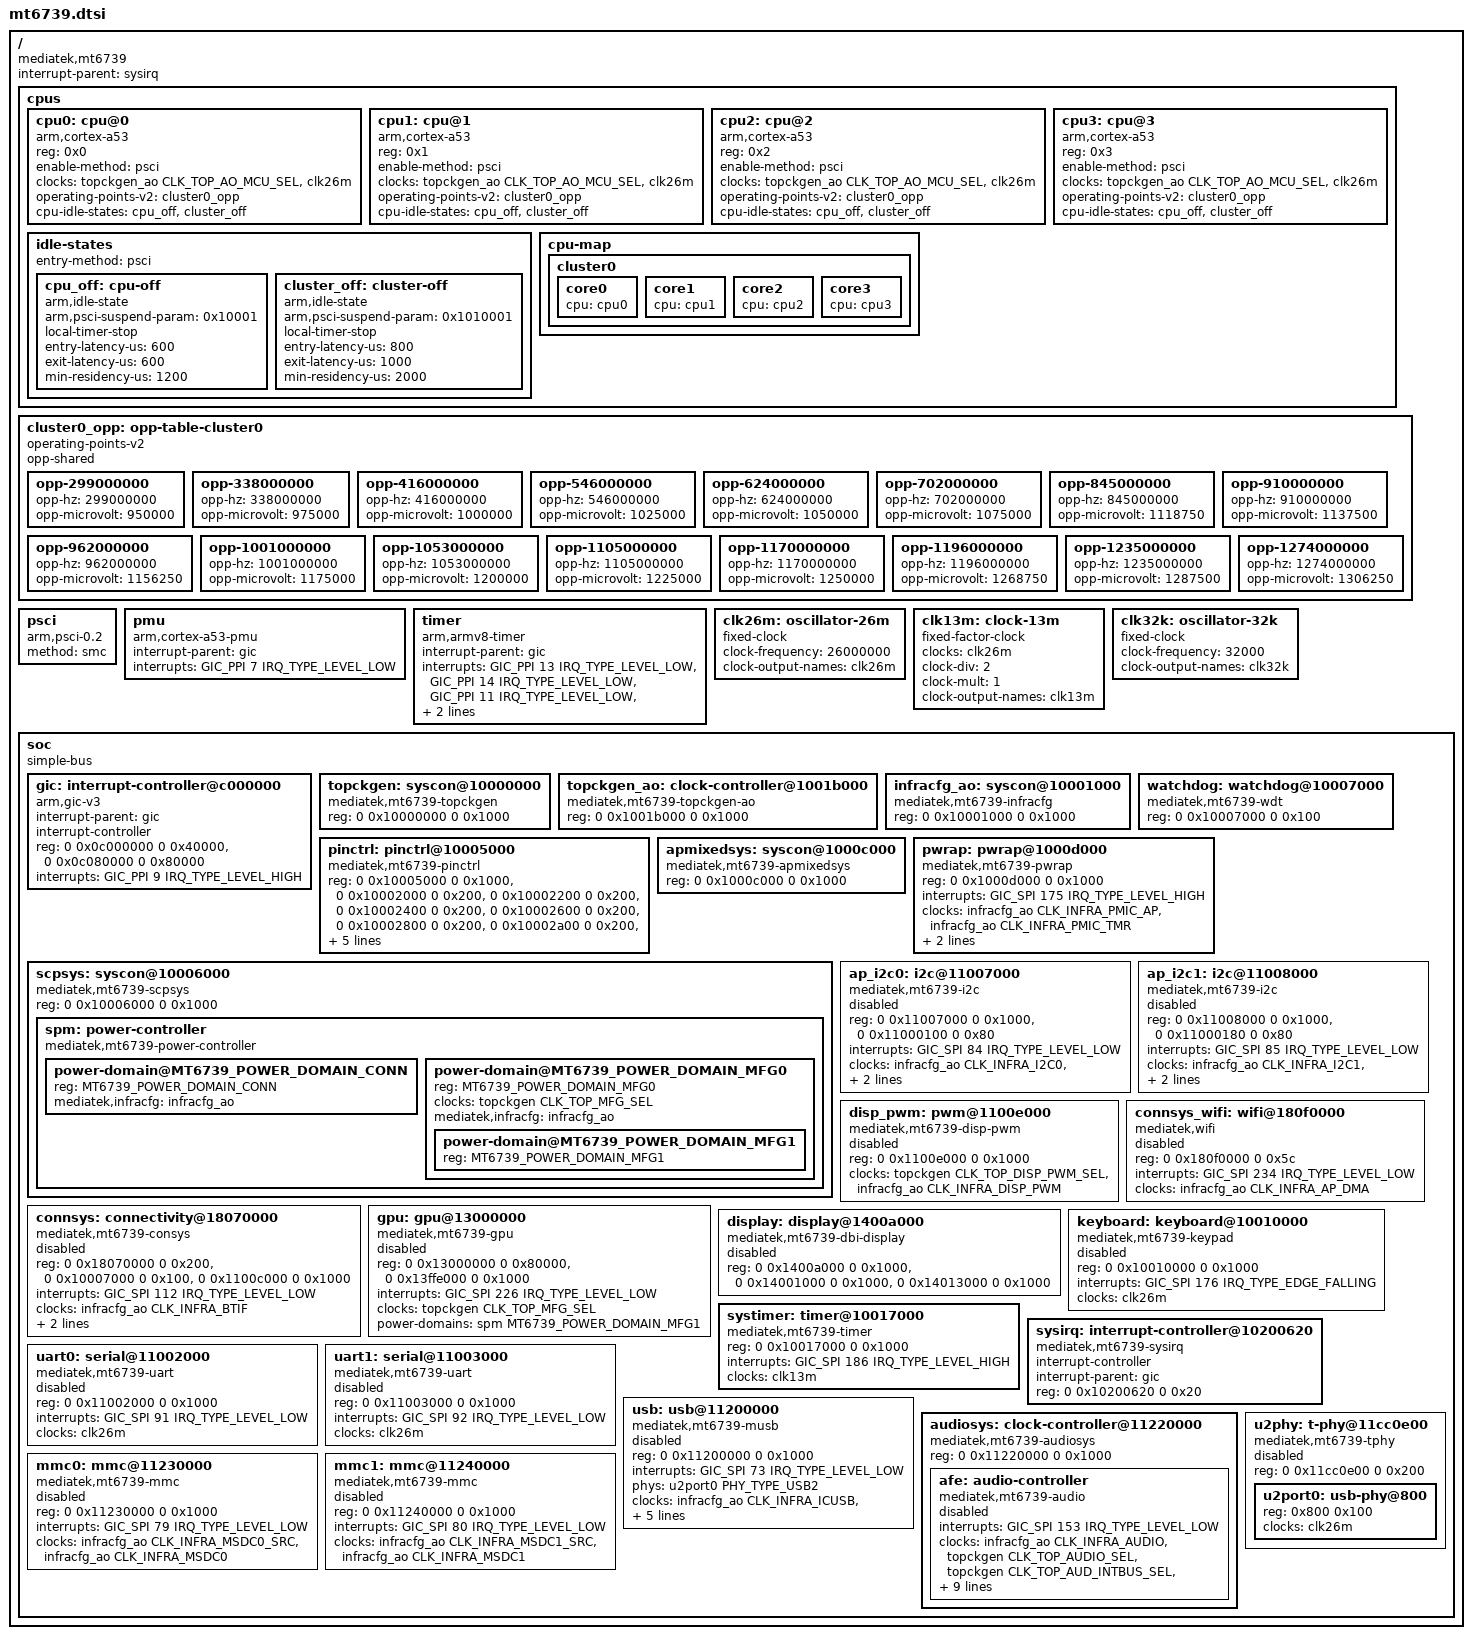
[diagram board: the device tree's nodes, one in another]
// SPDX-License-Identifier: GPL-2.0-only OR MIT

#include <dt-bindings/clock/mediatek,mt6739-clk.h>
#include <dt-bindings/interrupt-controller/arm-gic.h>
#include <dt-bindings/interrupt-controller/irq.h>
#include <dt-bindings/phy/phy.h>
#include <dt-bindings/pinctrl/mt6739-pinfunc.h>
#include <dt-bindings/reset/mediatek,mt6739-resets.h>
#include <dt-bindings/power/mediatek,mt6739-power-controller.h>

/ {
	compatible = "mediatek,mt6739";
	interrupt-parent = <&sysirq>;
	#address-cells = <2>;
	#size-cells = <2>;

	cpus {
		#address-cells = <1>;
		#size-cells = <0>;

		cpu0: cpu@0 {
			device_type = "cpu";
			compatible = "arm,cortex-a53";
			reg = <0x0>;
			enable-method = "psci";
			clocks = <&topckgen_ao CLK_TOP_AO_MCU_SEL>, <&clk26m>;
			clock-names = "cpu", "intermediate";
			operating-points-v2 = <&cluster0_opp>;
			cpu-idle-states = <&cpu_off &cluster_off>;
		};

		cpu1: cpu@1 {
			device_type = "cpu";
			compatible = "arm,cortex-a53";
			reg = <0x1>;
			enable-method = "psci";
			clocks = <&topckgen_ao CLK_TOP_AO_MCU_SEL>, <&clk26m>;
			clock-names = "cpu", "intermediate";
			operating-points-v2 = <&cluster0_opp>;
			cpu-idle-states = <&cpu_off &cluster_off>;
		};

		cpu2: cpu@2 {
			device_type = "cpu";
			compatible = "arm,cortex-a53";
			reg = <0x2>;
			enable-method = "psci";
			clocks = <&topckgen_ao CLK_TOP_AO_MCU_SEL>, <&clk26m>;
			clock-names = "cpu", "intermediate";
			operating-points-v2 = <&cluster0_opp>;
			cpu-idle-states = <&cpu_off &cluster_off>;
		};

		cpu3: cpu@3 {
			device_type = "cpu";
			compatible = "arm,cortex-a53";
			reg = <0x3>;
			enable-method = "psci";
			clocks = <&topckgen_ao CLK_TOP_AO_MCU_SEL>, <&clk26m>;
			clock-names = "cpu", "intermediate";
			operating-points-v2 = <&cluster0_opp>;
			cpu-idle-states = <&cpu_off &cluster_off>;
		};

		idle-states {
			entry-method = "psci";

			cpu_off: cpu-off {
				compatible = "arm,idle-state";
				arm,psci-suspend-param = <0x10001>;
				local-timer-stop;
				entry-latency-us = <600>;
				exit-latency-us = <600>;
				min-residency-us = <1200>;
			};

			cluster_off: cluster-off {
				compatible = "arm,idle-state";
				arm,psci-suspend-param = <0x1010001>;
				local-timer-stop;
				entry-latency-us = <800>;
				exit-latency-us = <1000>;
				min-residency-us = <2000>;
			};
		};

		cpu-map {
			cluster0 {
				core0 {
					cpu = <&cpu0>;
				};

				core1 {
					cpu = <&cpu1>;
				};

				core2 {
					cpu = <&cpu2>;
				};

				core3 {
					cpu = <&cpu3>;
				};
			};
		};
	};

	/* The vendor "FY" table, for efuse segment 0xad. */
	cluster0_opp: opp-table-cluster0 {
		compatible = "operating-points-v2";
		opp-shared;

		opp-299000000 {
			opp-hz = /bits/ 64 <299000000>;
			opp-microvolt = <950000>;
		};

		opp-338000000 {
			opp-hz = /bits/ 64 <338000000>;
			opp-microvolt = <975000>;
		};

		opp-416000000 {
			opp-hz = /bits/ 64 <416000000>;
			opp-microvolt = <1000000>;
		};

		opp-546000000 {
			opp-hz = /bits/ 64 <546000000>;
			opp-microvolt = <1025000>;
		};

		opp-624000000 {
			opp-hz = /bits/ 64 <624000000>;
			opp-microvolt = <1050000>;
		};

		opp-702000000 {
			opp-hz = /bits/ 64 <702000000>;
			opp-microvolt = <1075000>;
		};

		opp-845000000 {
			opp-hz = /bits/ 64 <845000000>;
			opp-microvolt = <1118750>;
		};

		opp-910000000 {
			opp-hz = /bits/ 64 <910000000>;
			opp-microvolt = <1137500>;
		};

		opp-962000000 {
			opp-hz = /bits/ 64 <962000000>;
			opp-microvolt = <1156250>;
		};

		opp-1001000000 {
			opp-hz = /bits/ 64 <1001000000>;
			opp-microvolt = <1175000>;
		};

		opp-1053000000 {
			opp-hz = /bits/ 64 <1053000000>;
			opp-microvolt = <1200000>;
		};

		opp-1105000000 {
			opp-hz = /bits/ 64 <1105000000>;
			opp-microvolt = <1225000>;
		};

		opp-1170000000 {
			opp-hz = /bits/ 64 <1170000000>;
			opp-microvolt = <1250000>;
		};

		opp-1196000000 {
			opp-hz = /bits/ 64 <1196000000>;
			opp-microvolt = <1268750>;
		};

		opp-1235000000 {
			opp-hz = /bits/ 64 <1235000000>;
			opp-microvolt = <1287500>;
		};

		opp-1274000000 {
			opp-hz = /bits/ 64 <1274000000>;
			opp-microvolt = <1306250>;
		};
	};

	psci {
		compatible = "arm,psci-0.2";
		method = "smc";
	};

	pmu {
		compatible = "arm,cortex-a53-pmu";
		interrupt-parent = <&gic>;
		interrupts = <GIC_PPI 7 IRQ_TYPE_LEVEL_LOW>;
	};

	timer {
		compatible = "arm,armv8-timer";
		interrupt-parent = <&gic>;
		interrupts = <GIC_PPI 13 IRQ_TYPE_LEVEL_LOW>,
			     <GIC_PPI 14 IRQ_TYPE_LEVEL_LOW>,
			     <GIC_PPI 11 IRQ_TYPE_LEVEL_LOW>,
			     <GIC_PPI 10 IRQ_TYPE_LEVEL_LOW>;
		clock-frequency = <13000000>;
	};

	clk26m: oscillator-26m {
		compatible = "fixed-clock";
		#clock-cells = <0>;
		clock-frequency = <26000000>;
		clock-output-names = "clk26m";
	};

	clk13m: clock-13m {
		compatible = "fixed-factor-clock";
		#clock-cells = <0>;
		clocks = <&clk26m>;
		clock-div = <2>;
		clock-mult = <1>;
		clock-output-names = "clk13m";
	};

	clk32k: oscillator-32k {
		compatible = "fixed-clock";
		#clock-cells = <0>;
		clock-frequency = <32000>;
		clock-output-names = "clk32k";
	};

	soc {
		compatible = "simple-bus";
		#address-cells = <2>;
		#size-cells = <2>;
		ranges;

		gic: interrupt-controller@c000000 {
			compatible = "arm,gic-v3";
			#interrupt-cells = <3>;
			interrupt-parent = <&gic>;
			interrupt-controller;
			reg = <0 0x0c000000 0 0x40000>,
			      <0 0x0c080000 0 0x80000>;
			interrupts = <GIC_PPI 9 IRQ_TYPE_LEVEL_HIGH>;
		};

		topckgen: syscon@10000000 {
			compatible = "mediatek,mt6739-topckgen";
			reg = <0 0x10000000 0 0x1000>;
			#clock-cells = <1>;
		};

		topckgen_ao: clock-controller@1001b000 {
			compatible = "mediatek,mt6739-topckgen-ao";
			reg = <0 0x1001b000 0 0x1000>;
			#clock-cells = <1>;
		};

		infracfg_ao: syscon@10001000 {
			compatible = "mediatek,mt6739-infracfg";
			reg = <0 0x10001000 0 0x1000>;
			#clock-cells = <1>;
			#reset-cells = <1>;
		};

		watchdog: watchdog@10007000 {
			compatible = "mediatek,mt6739-wdt",
				     "mediatek,mt6589-wdt";
			reg = <0 0x10007000 0 0x100>;
			#reset-cells = <1>;
		};

		pinctrl: pinctrl@10005000 {
			compatible = "mediatek,mt6739-pinctrl";
			reg = <0 0x10005000 0 0x1000>,
			      <0 0x10002000 0 0x200>,
			      <0 0x10002200 0 0x200>,
			      <0 0x10002400 0 0x200>,
			      <0 0x10002600 0 0x200>,
			      <0 0x10002800 0 0x200>,
			      <0 0x10002a00 0 0x200>,
			      <0 0x10002c00 0 0x200>,
			      <0 0x1000b000 0 0x1000>;
			reg-names = "gpio", "iocfg_lt", "iocfg_lm", "iocfg_lb",
				    "iocfg_bl", "iocfg_bm", "iocfg_rb", "iocfg_rt",
				    "eint";
			gpio-controller;
			#gpio-cells = <2>;
			gpio-ranges = <&pinctrl 0 0 169>;
			interrupt-controller;
			#interrupt-cells = <2>;
			interrupts = <GIC_SPI 167 IRQ_TYPE_LEVEL_HIGH>;
		};

		apmixedsys: syscon@1000c000 {
			compatible = "mediatek,mt6739-apmixedsys";
			reg = <0 0x1000c000 0 0x1000>;
			#clock-cells = <1>;
		};

		pwrap: pwrap@1000d000 {
			compatible = "mediatek,mt6739-pwrap";
			reg = <0 0x1000d000 0 0x1000>;
			reg-names = "pwrap";
			interrupts = <GIC_SPI 175 IRQ_TYPE_LEVEL_HIGH>;
			clocks = <&infracfg_ao CLK_INFRA_PMIC_AP>,
				 <&infracfg_ao CLK_INFRA_PMIC_TMR>;
			clock-names = "spi", "wrap";
			resets = <&infracfg_ao MT6739_INFRACFG_AO_PMIC_WRAP_SW_RST>;
			reset-names = "pwrap";
		};

		scpsys: syscon@10006000 {
			compatible = "mediatek,mt6739-scpsys", "syscon", "simple-mfd";
			reg = <0 0x10006000 0 0x1000>;

			spm: power-controller {
				compatible = "mediatek,mt6739-power-controller";
				#address-cells = <1>;
				#size-cells = <0>;
				#power-domain-cells = <1>;

				power-domain@MT6739_POWER_DOMAIN_CONN {
					reg = <MT6739_POWER_DOMAIN_CONN>;
					mediatek,infracfg = <&infracfg_ao>;
					#power-domain-cells = <0>;
				};

				power-domain@MT6739_POWER_DOMAIN_MFG0 {
					reg = <MT6739_POWER_DOMAIN_MFG0>;
					clocks = <&topckgen CLK_TOP_MFG_SEL>;
					clock-names = "mfg";
					mediatek,infracfg = <&infracfg_ao>;
					#address-cells = <1>;
					#size-cells = <0>;
					#power-domain-cells = <0>;

					power-domain@MT6739_POWER_DOMAIN_MFG1 {
						reg = <MT6739_POWER_DOMAIN_MFG1>;
						#power-domain-cells = <0>;
					};
				};
			};
		};

		ap_i2c0: i2c@11007000 {
			compatible = "mediatek,mt6739-i2c";
			reg = <0 0x11007000 0 0x1000>,
			      <0 0x11000100 0 0x80>;
			interrupts = <GIC_SPI 84 IRQ_TYPE_LEVEL_LOW>;
			clocks = <&infracfg_ao CLK_INFRA_I2C0>,
				 <&infracfg_ao CLK_INFRA_AP_DMA>;
			clock-names = "main", "dma";
			clock-div = <5>;
			#address-cells = <1>;
			#size-cells = <0>;
			status = "disabled";
		};

		ap_i2c1: i2c@11008000 {
			compatible = "mediatek,mt6739-i2c";
			reg = <0 0x11008000 0 0x1000>,
			      <0 0x11000180 0 0x80>;
			interrupts = <GIC_SPI 85 IRQ_TYPE_LEVEL_LOW>;
			clocks = <&infracfg_ao CLK_INFRA_I2C1>,
				 <&infracfg_ao CLK_INFRA_AP_DMA>;
			clock-names = "main", "dma";
			clock-div = <5>;
			#address-cells = <1>;
			#size-cells = <0>;
			status = "disabled";
		};

		disp_pwm: pwm@1100e000 {
			compatible = "mediatek,mt6739-disp-pwm",
				     "mediatek,mt8183-disp-pwm";
			reg = <0 0x1100e000 0 0x1000>;
			clocks = <&topckgen CLK_TOP_DISP_PWM_SEL>,
				 <&infracfg_ao CLK_INFRA_DISP_PWM>;
			clock-names = "main", "mm";
			#pwm-cells = <2>;
			status = "disabled";
		};

		connsys: connectivity@18070000 {
			compatible = "mediatek,mt6739-consys";
			reg = <0 0x18070000 0 0x200>,
			      <0 0x10007000 0 0x100>,
			      <0 0x1100c000 0 0x1000>;
			reg-names = "conn", "toprgu", "btif";
			interrupts = <GIC_SPI 112 IRQ_TYPE_LEVEL_LOW>;
			interrupt-names = "btif";
			clocks = <&infracfg_ao CLK_INFRA_BTIF>;
			clock-names = "btif";
			power-domains = <&spm MT6739_POWER_DOMAIN_CONN>;
			mediatek,infracfg = <&infracfg_ao>;
			status = "disabled";
		};

		connsys_wifi: wifi@180f0000 {
			compatible = "mediatek,wifi";
			reg = <0 0x180f0000 0 0x5c>;
			interrupts = <GIC_SPI 234 IRQ_TYPE_LEVEL_LOW>;
			clocks = <&infracfg_ao CLK_INFRA_AP_DMA>;
			clock-names = "wifi-dma";
			status = "disabled";
		};

		gpu: gpu@13000000 {
			compatible = "mediatek,mt6739-gpu", "img,img-rogue";
			reg = <0 0x13000000 0 0x80000>,
			      <0 0x13ffe000 0 0x1000>;
			interrupts = <GIC_SPI 226 IRQ_TYPE_LEVEL_LOW>;
			clocks = <&topckgen CLK_TOP_MFG_SEL>;
			clock-names = "core";
			power-domains = <&spm MT6739_POWER_DOMAIN_MFG1>;
			status = "disabled";
		};

		display: display@1400a000 {
			compatible = "mediatek,mt6739-dbi-display";
			reg = <0 0x1400a000 0 0x1000>,
			      <0 0x14001000 0 0x1000>,
			      <0 0x14013000 0 0x1000>;
			reg-names = "ovl", "mutex", "dbi";
			status = "disabled";
		};

		keyboard: keyboard@10010000 {
			compatible = "mediatek,mt6739-keypad",
				     "mediatek,mt6779-keypad";
			reg = <0 0x10010000 0 0x1000>;
			interrupts = <GIC_SPI 176 IRQ_TYPE_EDGE_FALLING>;
			clocks = <&clk26m>;
			clock-names = "kpd";
			status = "disabled";
		};

		systimer: timer@10017000 {
			compatible = "mediatek,mt6739-timer",
				     "mediatek,mt6765-timer";
			reg = <0 0x10017000 0 0x1000>;
			interrupts = <GIC_SPI 186 IRQ_TYPE_LEVEL_HIGH>;
			clocks = <&clk13m>;
		};

		sysirq: interrupt-controller@10200620 {
			compatible = "mediatek,mt6739-sysirq",
				     "mediatek,mt6577-sysirq";
			interrupt-controller;
			#interrupt-cells = <3>;
			interrupt-parent = <&gic>;
			reg = <0 0x10200620 0 0x20>;
		};

		uart0: serial@11002000 {
			compatible = "mediatek,mt6739-uart",
				     "mediatek,mt6577-uart";
			reg = <0 0x11002000 0 0x1000>;
			interrupts = <GIC_SPI 91 IRQ_TYPE_LEVEL_LOW>;
			clocks = <&clk26m>;
			clock-names = "baud";
			status = "disabled";
		};

		uart1: serial@11003000 {
			compatible = "mediatek,mt6739-uart",
				     "mediatek,mt6577-uart";
			reg = <0 0x11003000 0 0x1000>;
			interrupts = <GIC_SPI 92 IRQ_TYPE_LEVEL_LOW>;
			clocks = <&clk26m>;
			clock-names = "baud";
			status = "disabled";
		};

		usb: usb@11200000 {
			compatible = "mediatek,mt6739-musb", "mediatek,mtk-musb";
			reg = <0 0x11200000 0 0x1000>;
			interrupts = <GIC_SPI 73 IRQ_TYPE_LEVEL_LOW>;
			interrupt-names = "mc";
			phys = <&u2port0 PHY_TYPE_USB2>;
			clocks = <&infracfg_ao CLK_INFRA_ICUSB>,
				 <&topckgen CLK_TOP_USB_TOP_SEL>,
				 <&topckgen CLK_TOP_UNIVPLL3_D4>;
			clock-names = "main", "mcu", "univpll";
			assigned-clocks = <&topckgen CLK_TOP_USB_TOP_SEL>;
			assigned-clock-parents = <&topckgen CLK_TOP_UNIVPLL3_D4>;
			status = "disabled";
		};

		audiosys: clock-controller@11220000 {
			compatible = "mediatek,mt6739-audiosys", "syscon";
			reg = <0 0x11220000 0 0x1000>;
			#clock-cells = <1>;

			afe: audio-controller {
				compatible = "mediatek,mt6739-audio";
				interrupts = <GIC_SPI 153 IRQ_TYPE_LEVEL_LOW>;
				clocks = <&infracfg_ao CLK_INFRA_AUDIO>,
					 <&topckgen CLK_TOP_AUDIO_SEL>,
					 <&topckgen CLK_TOP_AUD_INTBUS_SEL>,
					 <&audiosys CLK_AUDIO_AFE>,
					 <&audiosys CLK_AUDIO_DAC>,
					 <&audiosys CLK_AUDIO_DAC_PREDIS>,
					 <&audiosys CLK_AUDIO_ADC>,
					 <&infracfg_ao CLK_INFRA_AUDIO_26M_BCLK>;
				clock-names = "aud_infra_clk",
					      "top_mux_audio",
					      "top_mux_aud_intbus",
					      "aud_afe_clk",
					      "aud_dac_clk",
					      "aud_dac_predis_clk",
					      "aud_adc_clk",
					      "mtkaif_26m_clk";
				assigned-clocks = <&topckgen CLK_TOP_AUDIO_SEL>,
						  <&topckgen CLK_TOP_AUD_INTBUS_SEL>;
				assigned-clock-parents = <&clk26m>,
							 <&topckgen CLK_TOP_SYSPLL1_D4>;
				status = "disabled";
			};
		};

		mmc0: mmc@11230000 {
			compatible = "mediatek,mt6739-mmc", "mediatek,mt6779-mmc";
			reg = <0 0x11230000 0 0x1000>;
			interrupts = <GIC_SPI 79 IRQ_TYPE_LEVEL_LOW>;
			clocks = <&infracfg_ao CLK_INFRA_MSDC0_SRC>,
				 <&infracfg_ao CLK_INFRA_MSDC0>;
			clock-names = "source", "hclk";
			status = "disabled";
		};

		mmc1: mmc@11240000 {
			compatible = "mediatek,mt6739-mmc", "mediatek,mt6779-mmc";
			reg = <0 0x11240000 0 0x1000>;
			interrupts = <GIC_SPI 80 IRQ_TYPE_LEVEL_LOW>;
			clocks = <&infracfg_ao CLK_INFRA_MSDC1_SRC>,
				 <&infracfg_ao CLK_INFRA_MSDC1>;
			clock-names = "source", "hclk";
			status = "disabled";
		};

		u2phy: t-phy@11cc0e00 {
			compatible = "mediatek,mt6739-tphy",
				     "mediatek,generic-tphy-v1";
			reg = <0 0x11cc0e00 0 0x200>;
			#address-cells = <1>;
			#size-cells = <1>;
			ranges = <0 0 0x11cc0000 0x1000>;
			status = "disabled";

			u2port0: usb-phy@800 {
				reg = <0x800 0x100>;
				clocks = <&clk26m>;
				clock-names = "ref";
				#phy-cells = <1>;
			};
		};
	};
};
